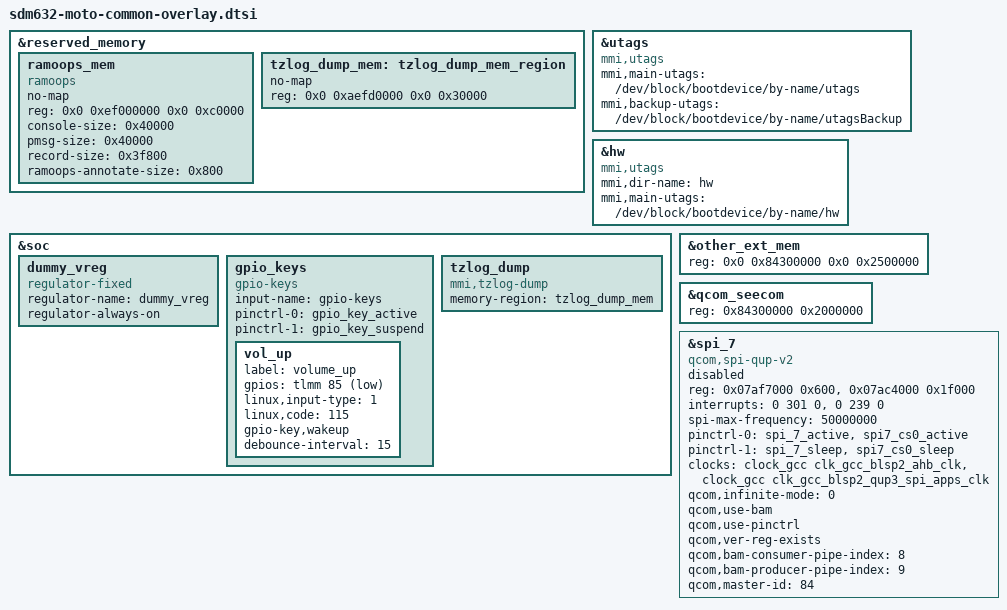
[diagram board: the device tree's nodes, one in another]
/*
 * Copyright (c) 2017-2018, The Linux Foundation. All rights reserved.
 *
 * This program is free software; you can redistribute it and/or modify
 * it under the terms of the GNU General Public License version 2 and
 * only version 2 as published by the Free Software Foundation.
 *
 * This program is distributed in the hope that it will be useful,
 * but WITHOUT ANY WARRANTY; without even the implied warranty of
 * MERCHANTABILITY or FITNESS FOR A PARTICULAR PURPOSE.  See the
 * GNU General Public License for more details.
 */

#include "sdm632-moto-pinctrl-overlay.dtsi"

&reserved_memory {
	ramoops_mem {
		compatible = "ramoops";
		no-map;
		reg = <0x0 0xef000000 0x0 0xc0000>;
		console-size = <0x40000>;
		pmsg-size = <0x40000>;
		record-size = <0x3f800>;
		ramoops-annotate-size = <0x800>;
	};

	tzlog_dump_mem: tzlog_dump_mem_region {
		no-map;
		reg = <0x0 0xaefd0000 0x0 0x30000>;
	};
};

&utags {
	compatible = "mmi,utags";
	mmi,main-utags = "/dev/block/bootdevice/by-name/utags";
	mmi,backup-utags = "/dev/block/bootdevice/by-name/utagsBackup";
};

&hw {
	compatible = "mmi,utags";
	mmi,dir-name = "hw";
	mmi,main-utags = "/dev/block/bootdevice/by-name/hw";
};

&soc{
	dummy_vreg: dummy_vreg {
		compatible = "regulator-fixed";
		status = "ok";
		regulator-name = "dummy_vreg";
		regulator-always-on;
	};

	gpio_keys {
		compatible = "gpio-keys";
		input-name = "gpio-keys";
		pinctrl-names = "tlmm_gpio_key_active","tlmm_gpio_key_suspend";
		pinctrl-0 = <&gpio_key_active>;
		pinctrl-1 = <&gpio_key_suspend>;

		vol_up {
			label = "volume_up";
			gpios = <&tlmm 85 0x1>;
			linux,input-type = <1>;
			linux,code = <115>;
			gpio-key,wakeup;
			debounce-interval = <15>;
		};
	};

	tzlog_dump {
		compatible = "mmi,tzlog-dump";
		memory-region = <&tzlog_dump_mem>;
	};
};
&other_ext_mem {
	reg = <0x0 0x84300000 0x0 0x2500000>;
};

&qcom_seecom {
	reg = <0x84300000 0x2000000>;
};

&spi_7 { /* BLSP2 QUP3 */
	compatible = "qcom,spi-qup-v2";
	#address-cells = <1>;
	#size-cells = <0>;
	reg-names = "spi_physical", "spi_bam_physical";
	reg = <0x07af7000 0x600>,
		<0x07ac4000 0x1f000>;
	interrupt-names = "spi_irq", "spi_bam_irq";
	interrupts = <0 301 0>, <0 239 0>;
	spi-max-frequency = <50000000>;
	pinctrl-names = "spi_default", "spi_sleep";
	pinctrl-0 = <&spi_7_active &spi7_cs0_active>;
	pinctrl-1 = <&spi_7_sleep &spi7_cs0_sleep>;
	clocks = <&clock_gcc clk_gcc_blsp2_ahb_clk>,
		<&clock_gcc clk_gcc_blsp2_qup3_spi_apps_clk>;
	clock-names = "iface_clk", "core_clk";
	qcom,infinite-mode = <0>;
	qcom,use-bam;
	qcom,use-pinctrl;
	qcom,ver-reg-exists;
	qcom,bam-consumer-pipe-index = <8>;
	qcom,bam-producer-pipe-index = <9>;
	qcom,master-id = <84>;
	status = "disabled";
};
